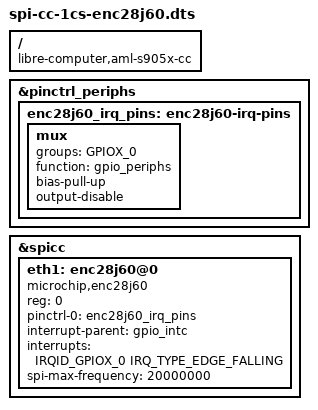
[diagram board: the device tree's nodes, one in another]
// SPDX-License-Identifier: (GPL-2.0-or-later OR MIT)
/*
 * Copyright (c) 2017 BayLibre, SAS.
 * Author: Neil Armstrong <narmstrong@baylibre.com>
 */
/*
 * Summary: ENC28J60 SPI ethernet on SPICC CS0.
 *
 * Pins (Header.Pin  Name  Pad  Ref — cross-ref gpio.map):
 *   7J1.19   GPIOX_8       B4      BTPCM_DOUT
 *   7J1.21   GPIOX_9       B3      BTPCM_DIN
 *   7J1.22   GPIOX_0       A2      WIFI_SD_D0
 *   7J1.23   GPIOX_11      C4      BTPCM_CLK
 *   7J1.24   GPIOX_10      C5      BTPCM_SYNC
 *
 * Requires: spi-cc-1cs
 *
 * Notes:
 *   SPI bus pins (7J1 19/21/23/24) come from the spi-cc-1cs bus overlay.
 *   IRQ: GPIOX_0 = 7J1 pin 22 (edge-falling; ENC28J60 INT is open-drain).
 *   pinctrl forces GPIOX_0 to gpio_periphs (not SDIO_D0) as input + pull-up.
 */
/dts-v1/;
/plugin/;

#include <dt-bindings/gpio/gpio.h>
#include <dt-bindings/gpio/meson-gxl-gpio.h>
#include <dt-bindings/interrupt-controller/irq.h>
#include <dt-bindings/interrupt-controller/amlogic,meson-gxl-gpio-intc.h>

/ {
	compatible = "libre-computer,aml-s905x-cc",
		     "libretech,aml-s905x-cc",
		     "libre-computer,aml-s905x-cc-v2",
		     "libretech,aml-s905x-cc-v2",
		"libre-computer,aml-s905x-cc-v3",
		"libretech,aml-s905x-cc-v3",
		     "amlogic,s905x",
		     "amlogic,meson-gxl";

	fragment@0 {
		target = <&pinctrl_periphs>;

		__overlay__ {
			enc28j60_irq_pins: enc28j60-irq-pins {
				mux {
					groups = "GPIOX_0";
					function = "gpio_periphs";
					bias-pull-up;
					output-disable;
				};
			};
		};
	};

	fragment@1 {
		target = <&spicc>;

		__overlay__ {
			#address-cells = <1>;
			#size-cells = <0>;

			eth1: enc28j60@0 {
				compatible = "microchip,enc28j60";
				reg = <0>;
				pinctrl-names = "default";
				pinctrl-0 = <&enc28j60_irq_pins>;
				interrupt-parent = <&gpio_intc>;
				interrupts = <IRQID_GPIOX_0 IRQ_TYPE_EDGE_FALLING>;
				spi-max-frequency = <20000000>;
				status = "okay";
			};
		};
	};
};
